# MSPM0L130X register map
Vendor: Texas Instruments; File version: This preliminary header file does not have a version number - build date: 2024-04-29 21:56:11
CPU: CM0 r0p1, little endian, MPU, no FPU, 3 interrupt priority bits
Registers are 32-bit, read-write, reset 0x0 unless marked. A register's access mark holds for its fields unless they carry their own. Offsets are from the block's base; [hi:lo] are bit positions; lines under a group give offsets from that group; {n}, {i} and the like mark numbered series; 'fields as' and 'values as' point back to an identical list.

## CPUSS — CPUSSMMR
Base 0x40400000
0x10E0 CPUSS_EVT_MODE ro — Event Mode
  [1:0] INT_CFG — Event line mode select
    0=DISABLE (The interrupt or event line is disabled.); 1=SOFTWARE (Event handled by software. Software must clear the associated RIS flag.); 2=HARDWARE (Event handled by hardware. The hardware (another module) clears automatically the associated RIS flag.)
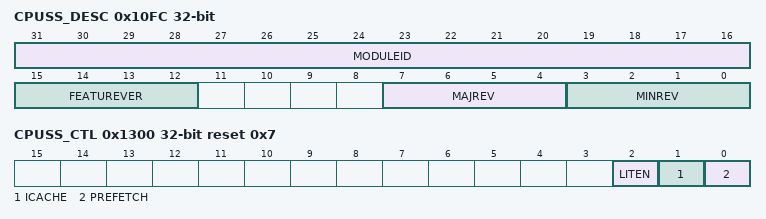
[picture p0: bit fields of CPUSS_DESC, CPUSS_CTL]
0x10FC CPUSS_DESC ro — Module Description
  [31:16] MODULEID — Module identification contains a unique peripheral identification number. The assignments are maintained in a central database for all of the platform modules to ensure uniqueness.
  [15:12] FEATUREVER — Feature Set for the module *instance*
  [7:4] MAJREV — Major rev of the IP
  [3:0] MINREV — Minor rev of the IP
{0x1100+0x2C*i} CPUSS_INT_GROUP0[{i}] (i=0..0) group
  0x00 CPUSS_INT_GROUP0_IIDX ro — Interrupt index
    [7:0] STAT — Interrupt index status
      0=NO_INTR (No pending interrupt); {v}=INT{v-1} (Interrupt {v-1}) (v=1..8)
  0x08 CPUSS_INT_GROUP0_IMASK ro reset 0xFF — Interrupt mask
    [7:0] INT — Masks the corresponding interrupt
      0=CLR (Interrupt is masked out); 1=SET (Interrupt will request an interrupt service routine and corresponding bit in MIS will be set)
  0x10 CPUSS_INT_GROUP0_RIS ro — Raw interrupt status
    [7:0] INT — Raw interrupt status for INT
      0=CLR (INT0 did not occur.); 1=SET (INT0 occurred.)
  0x18 CPUSS_INT_GROUP0_MIS ro — Masked interrupt status
    [0] INT — Masked interrupt status for INT0
      0=CLR (INT does not request an interrupt service routine); 1=SET (INT requests an interrupt service routine)
  0x20 CPUSS_INT_GROUP0_ISET wo — Interrupt set
    [0] INT — Sets INT in RIS register
      0=NO_EFFECT (Writing a 0 has no effect); 1=SET (RIS bit corresponding to INT is set)
  0x28 CPUSS_INT_GROUP0_ICLR wo — Interrupt clear
    [0] INT — Clears INT in RIS register
      0=NO_EFFECT (Writing a 0 has no effect); 1=CLR (RIS bit corresponding to INT is cleared)
{0x1130+0x2C*i} CPUSS_INT_GROUP1[{i}] (i=0..0) group
  0x00 CPUSS_INT_GROUP1_IIDX ro — Interrupt index
    fields as CPUSS_INT_GROUP0[0].CPUSS_INT_GROUP0_IIDX
  0x08 CPUSS_INT_GROUP1_IMASK ro reset 0xFF — Interrupt mask
    fields as CPUSS_INT_GROUP0[0].CPUSS_INT_GROUP0_IMASK
  0x10 CPUSS_INT_GROUP1_RIS ro — Raw interrupt status
    [0] INT — Raw interrupt status for INT
      0=CLR (INT0 did not occur.); 1=SET (INT0 occurred.)
  0x18 CPUSS_INT_GROUP1_MIS ro — Masked interrupt status
    fields as CPUSS_INT_GROUP0[0].CPUSS_INT_GROUP0_MIS
  0x20 CPUSS_INT_GROUP1_ISET wo — Interrupt set
    fields as CPUSS_INT_GROUP0[0].CPUSS_INT_GROUP0_ISET
  0x28 CPUSS_INT_GROUP1_ICLR wo — Interrupt clear
    fields as CPUSS_INT_GROUP0[0].CPUSS_INT_GROUP0_ICLR
0x1300 CPUSS_CTL reset 0x7 — Prefetch/Cache control
  [2] LITEN — Literal caching and prefetch enable. This bit is a subset of ICACHE/PREFETCH bit i.e. literal caching or literal prefetching will only happen if ICACHE or PREFETCH bits have been set respectively When enabled, the cache and prefetcher structures inside CPUSS will cache and prefetch literals When disabled, the cache and prefetcher structures inside CPUSS will not cache and prefetch literals
    0=DISABLE (Literal caching disabled); 1=ENABLE (Literal caching enabled)
  [1] ICACHE — Used to enable/disable Instruction caching on flash access.
    0=DISABLE (Disable instruction caching.); 1=ENABLE (Enable instruction caching.)
  [0] PREFETCH — Used to enable/disable instruction prefetch to Flash.
    0=DISABLE (Disable instruction prefetch.); 1=ENABLE (Enable instruction prefetch.)

## Notices in the file
Copyright (C) 2024 Texas Instruments Incorporated - http://www.ti.com
Redistribution and use in source and binary forms, with or without
modification, are permitted provided that the following conditions
are met:
Redistributions of source code must retain the above copyright
notice, this list of conditions and the following disclaimer.
Redistributions in binary form must reproduce the above copyright
notice, this list of conditions and the following disclaimer in the
documentation and/or other materials provided with the
distribution.
Neither the name of Texas Instruments Incorporated nor the names of
its contributors may be used to endorse or promote products derived
from this software without specific prior written permission.
THIS SOFTWARE IS PROVIDED BY THE COPYRIGHT HOLDERS AND CONTRIBUTORS
"AS IS" AND ANY EXPRESS OR IMPLIED WARRANTIES, INCLUDING, BUT NOT
LIMITED TO, THE IMPLIED WARRANTIES OF MERCHANTABILITY AND FITNESS FOR
A PARTICULAR PURPOSE ARE DISCLAIMED. IN NO EVENT SHALL THE COPYRIGHT
OWNER OR CONTRIBUTORS BE LIABLE FOR ANY DIRECT, INDIRECT, INCIDENTAL,
SPECIAL, EXEMPLARY, OR CONSEQUENTIAL DAMAGES (INCLUDING, BUT NOT
LIMITED TO, PROCUREMENT OF SUBSTITUTE GOODS OR SERVICES; LOSS OF USE,
DATA, OR PROFITS; OR BUSINESS INTERRUPTION) HOWEVER CAUSED AND ON ANY
THEORY OF LIABILITY, WHETHER IN CONTRACT, STRICT LIABILITY, OR TORT
(INCLUDING NEGLIGENCE OR OTHERWISE) ARISING IN ANY WAY OUT OF THE USE
OF THIS SOFTWARE, EVEN IF ADVISED OF THE POSSIBILITY OF SUCH DAMAGE.
